# S32R372 register map
Vendor: Freescale Semiconductor, Inc.; Series: Qorivva; File version: 1.6
Registers are 32-bit, read-write, reset 0x0 unless marked. A register's access mark holds for its fields unless they carry their own. Offsets are from the block's base; [hi:lo] are bit positions; {n}, {i} and the like mark numbered series; 'fields as' and 'values as' point back to an identical list.

## SIUL2
Base 0xFFFC0000; register names take the prefix SIUL2_
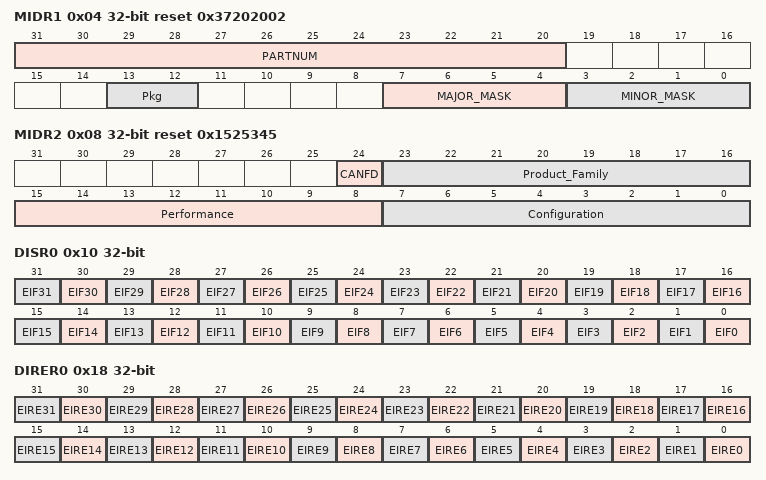
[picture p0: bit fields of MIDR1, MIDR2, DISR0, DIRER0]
0x04 MIDR1 ro reset 0x37202002 — SIUL2 MCU ID Register #1
  [31:20] PARTNUM — MCU Part Number
  [13:12] Pkg — Package details
    1=141MAPBGA Packeage; 2=257MAPBGA Package
  [7:4] MAJOR_MASK — Major Mask Revision
  [3:0] MINOR_MASK — Minor Mask Revision
0x08 MIDR2 ro reset 0x1525345 — SIUL2 MCU ID Register #2
  [24] CANFD
    0=CANFD is not supported; 1=CANFD is supported
  [23:16] Product_Family — Product Family Number
  [15:8] Performance — Performance of device, see
  [7:0] Configuration — Configuration of device, see
0x10 DISR0 — SIUL2 DMA/Interrupt Status Flag Register0
  [n] EIF{n} (n=4..31) — External Interrupt Status Flag x
    0=No interrupt event has occurred on the pad; 1=An interrupt event as defined by SIUL2_IREER[x] and SIUL2_IFEER[x] has occurred
  [n] EIF{n} (n=0..3) — External Interrupt Status Flag x
    0=No interrupt or DMA event has occurred on the pad; 1=An interrupt or DMA event as defined by SIUL2_IREER[x] and SIUL2_IFEER[x] has occurred
0x18 DIRER0 — SIUL2 DMA/Interrupt Request Enable Register0
  [n] EIRE{n} (n=4..31) — External Interrupt or DMA Request Enable x
    0=Interrupt or DMA requests from the corresponding EIF[x] bit are disabled; 1=Set EIF[x] bit causes an interrupt request
  [n] EIRE{n} (n=0..3) — External Interrupt or DMA Request Enable x
    0=Interrupt or DMA requests from the corresponding EIF[x] bit are disabled; 1=Set EIF[x] bit causes either a DMA or an interrupt request depending on DIRSR register
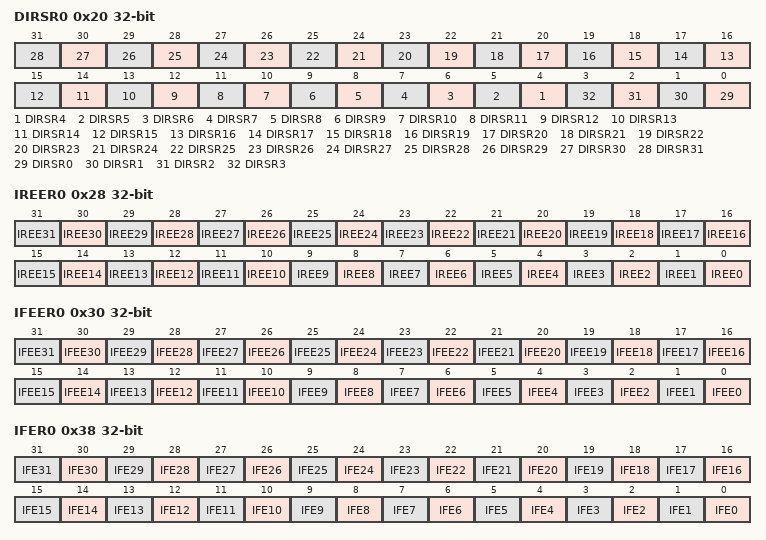
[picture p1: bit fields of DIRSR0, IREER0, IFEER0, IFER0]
0x20 DIRSR0 — SIUL2 DMA/Interrupt Request Select Register0
  [n] DIRSR{n} (n=4..31) — DMA/Interrupt Request Select Register-Selects between DMA request or external interrupt request when an edge-triggered event occurs on the corresponding pin
    0=Interrupt request is selected
  [n] DIRSR{n} (n=0..3) — DMA/Interrupt Request Select Register-Selects between DMA request or external interrupt request when an edge-triggered event occurs on the corresponding pin
    0=Interrupt request is selected; 1=DMA request is selected
0x28 IREER0 — SIUL2 Interrupt Rising-Edge Event Enable Register 0
  [all] fields
    0=Rising-edge event is disabled; 1=Rising-edge event is enabled
  [n] IREE{n} (n=0..31) — Enable rising-edge events to cause the EIF[x] bit to be set.
0x30 IFEER0 — SIUL2 Interrupt Falling-Edge Event Enable Register 0
  [all] fields
    0=Falling-edge event is disabled; 1=Falling-edge event is enabled
  [n] IFEE{n} (n=0..31) — Enable falling-edge events to cause the EIF[x] bit to be set.
0x38 IFER0 — SIUL2 Interrupt Filter Enable Register 0
  [all] fields
    0=Filter is disabled; 1=Filter is enabled
  [n] IFE{n} (n=0..31) — Enable digital glitch filter on the interrupt pad input.
{0x40+4i} IFMCR{i} (i=0..31) — SIUL2 Interrupt Filter Maximum Counter Register
  [3:0] MAXCNT — Maximum Interrupt Filter Counter setting
0xC0 IFCPR — SIUL2 Interrupt Filter Clock Prescaler Register
  [3:0] IFCP — Interrupt Filter Clock Prescaler setting
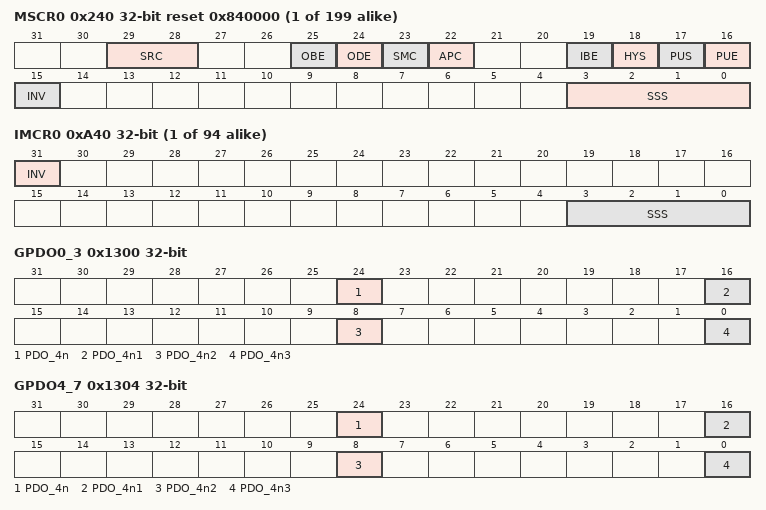
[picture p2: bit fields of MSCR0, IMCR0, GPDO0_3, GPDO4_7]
{0x240+4i} MSCR{i} (i=0..198) reset 0x840000 — SIUL2 Multiplexed Signal Configuration Register
  [29:28] SRC — Slew Rate Control
    0=Half drive strength with slew rate control; 1=Full drive strength with slew rate control; 2=Half drive strength without slew rate control; 3=Full drive strength without slew rate control
  [25] OBE — GPIO Output Buffer Enable
    0=Output driver disabled; 1=Output driver enabled
  [24] ODE — Open Drain EnableTo enable open drain both OBE and ODE bits need to be set.
    0=Open drain function disabled; 1=Open drain function enabled
  [23] SMC — Safe Mode Control
    0=Disable (the output buffer returns to its previous state when the chip leaves Safe mode); 1=Don't disable
  [22] APC — Analog Pad Control
    0=Disable (the switch is off); 1=Enable (another module can control the state of the switch)
  [19] IBE — Input Buffer Enable
    0=Disabled; 1=Enabled
  [18] HYS — Input Hysteresis
    0=Disabled; 1=Enabled
  [17] PUS — Pull Select
    0=Pulldown; 1=Pullup
  [16] PUE — Pull Enable
    0=Disabled; 1=Enabled
  [15] INV — Invert
    0=Don't invert; 1=Invert
  [3:0] SSS — Source Signal Select
{0xA40+4i} IMCR{i} (i=0..93) — SIUL2 Input Multiplexed Signal Configuration Register
  [31] INV — Invert
    0=Don't invert; 1=Invert
  [3:0] SSS — Source Signal Select
0x1300 GPDO0_3 — SIUL2 GPIO Pad Data Output Register
  [all] fields
    0=Logic low value is driven on the corresponding GPIO pad when the pad is configured as an output; 1=Logic high value is driven on the corresponding GPIO pad when the pad is configured as an output
  [24] PDO_4n — Pad Data Out
  [16] PDO_4n1 — Pad Data Out
  [8] PDO_4n2 — Pad Data Out
  [0] PDO_4n3 — Pad Data Out
0x1304 GPDO4_7 — SIUL2 GPIO Pad Data Output Register
  fields as GPDO0_3
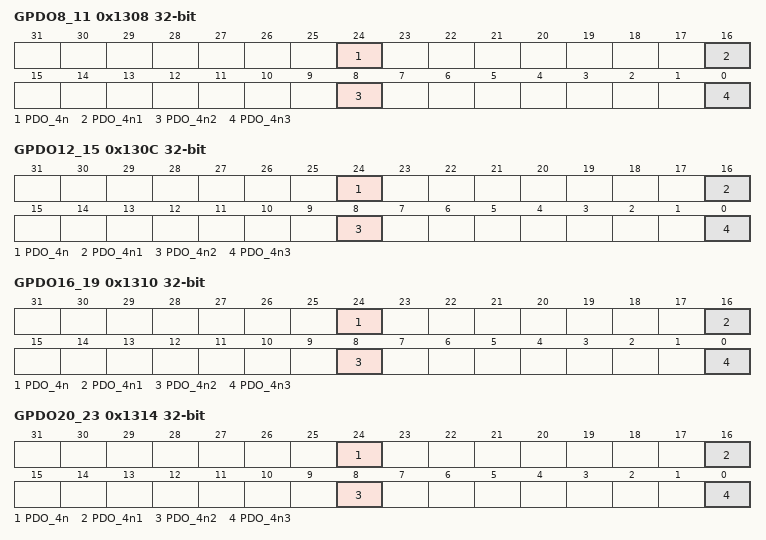
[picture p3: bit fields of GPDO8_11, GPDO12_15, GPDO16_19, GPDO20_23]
0x1308 GPDO8_11 — SIUL2 GPIO Pad Data Output Register
  fields as GPDO0_3
0x130C GPDO12_15 — SIUL2 GPIO Pad Data Output Register
  fields as GPDO0_3
0x1310 GPDO16_19 — SIUL2 GPIO Pad Data Output Register
  fields as GPDO0_3
0x1314 GPDO20_23 — SIUL2 GPIO Pad Data Output Register
  fields as GPDO0_3
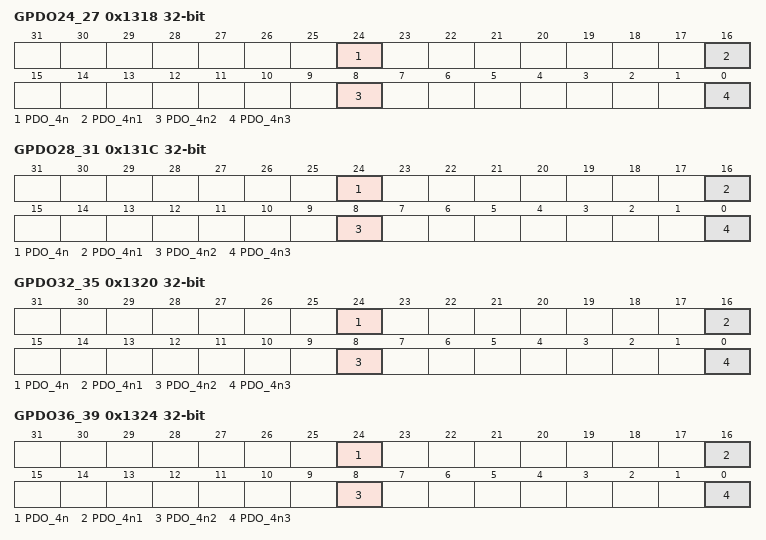
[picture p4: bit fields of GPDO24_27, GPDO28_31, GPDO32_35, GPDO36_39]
0x1318 GPDO24_27 — SIUL2 GPIO Pad Data Output Register
  fields as GPDO0_3
0x131C GPDO28_31 — SIUL2 GPIO Pad Data Output Register
  fields as GPDO0_3
0x1320 GPDO32_35 — SIUL2 GPIO Pad Data Output Register
  fields as GPDO0_3
0x1324 GPDO36_39 — SIUL2 GPIO Pad Data Output Register
  fields as GPDO0_3
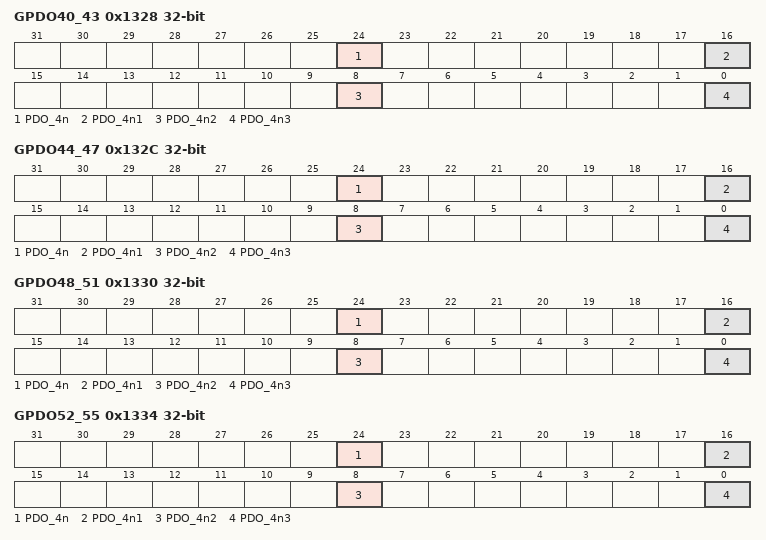
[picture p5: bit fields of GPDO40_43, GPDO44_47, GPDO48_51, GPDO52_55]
0x1328 GPDO40_43 — SIUL2 GPIO Pad Data Output Register
  fields as GPDO0_3
0x132C GPDO44_47 — SIUL2 GPIO Pad Data Output Register
  fields as GPDO0_3
0x1330 GPDO48_51 — SIUL2 GPIO Pad Data Output Register
  fields as GPDO0_3
0x1334 GPDO52_55 — SIUL2 GPIO Pad Data Output Register
  fields as GPDO0_3
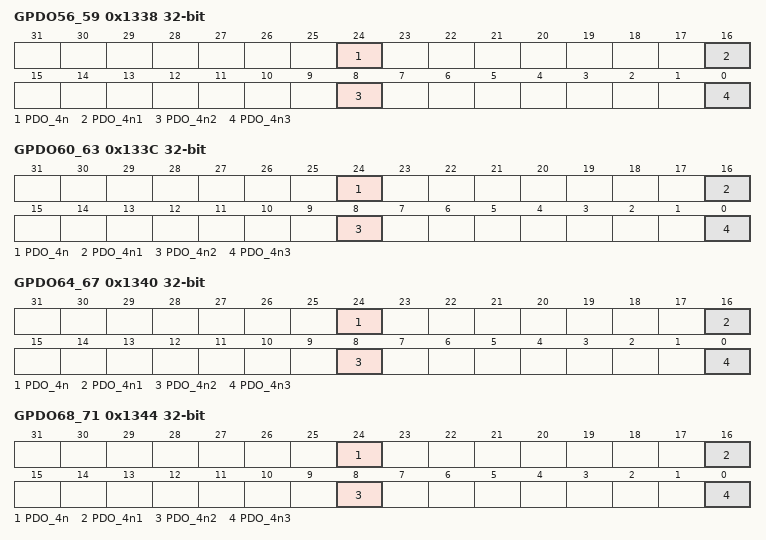
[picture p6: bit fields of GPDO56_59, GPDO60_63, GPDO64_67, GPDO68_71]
0x1338 GPDO56_59 — SIUL2 GPIO Pad Data Output Register
  fields as GPDO0_3
0x133C GPDO60_63 — SIUL2 GPIO Pad Data Output Register
  fields as GPDO0_3
0x1340 GPDO64_67 — SIUL2 GPIO Pad Data Output Register
  fields as GPDO0_3
0x1344 GPDO68_71 — SIUL2 GPIO Pad Data Output Register
  fields as GPDO0_3
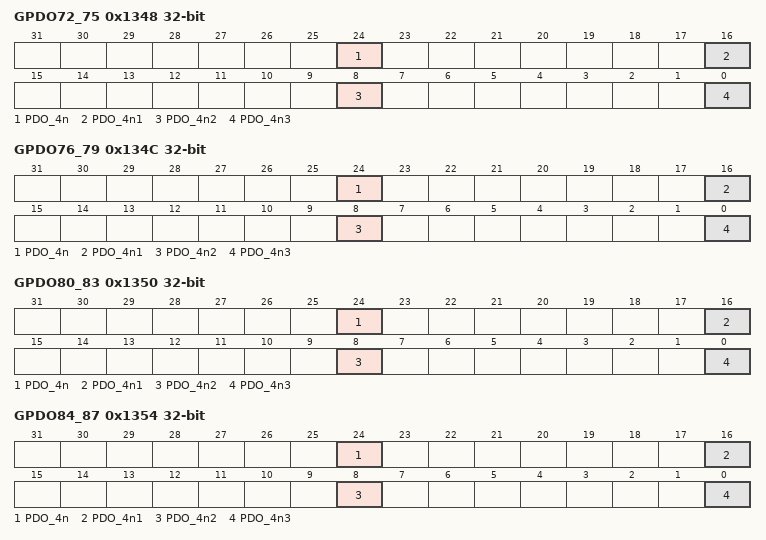
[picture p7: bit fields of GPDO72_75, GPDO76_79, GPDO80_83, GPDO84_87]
0x1348 GPDO72_75 — SIUL2 GPIO Pad Data Output Register
  fields as GPDO0_3
0x134C GPDO76_79 — SIUL2 GPIO Pad Data Output Register
  fields as GPDO0_3
0x1350 GPDO80_83 — SIUL2 GPIO Pad Data Output Register
  fields as GPDO0_3
0x1354 GPDO84_87 — SIUL2 GPIO Pad Data Output Register
  fields as GPDO0_3
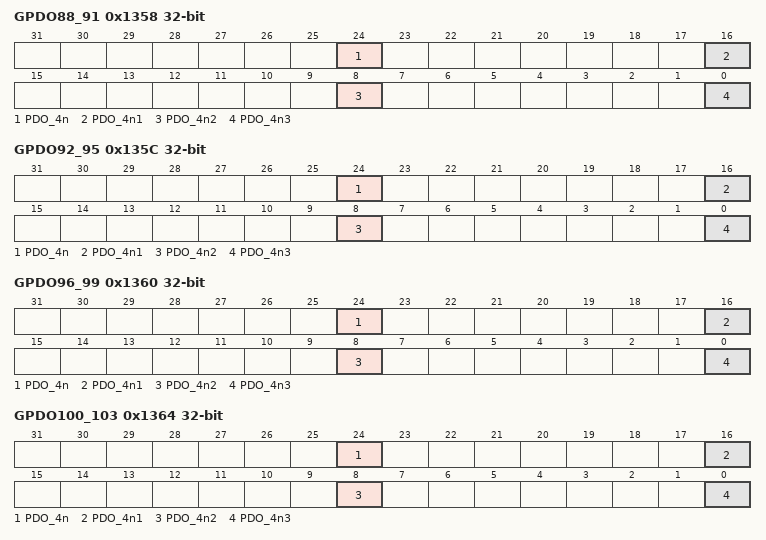
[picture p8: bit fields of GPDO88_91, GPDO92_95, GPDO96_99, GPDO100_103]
0x1358 GPDO88_91 — SIUL2 GPIO Pad Data Output Register
  fields as GPDO0_3
0x135C GPDO92_95 — SIUL2 GPIO Pad Data Output Register
  fields as GPDO0_3
0x1360 GPDO96_99 — SIUL2 GPIO Pad Data Output Register
  fields as GPDO0_3
0x1364 GPDO100_103 — SIUL2 GPIO Pad Data Output Register
  fields as GPDO0_3
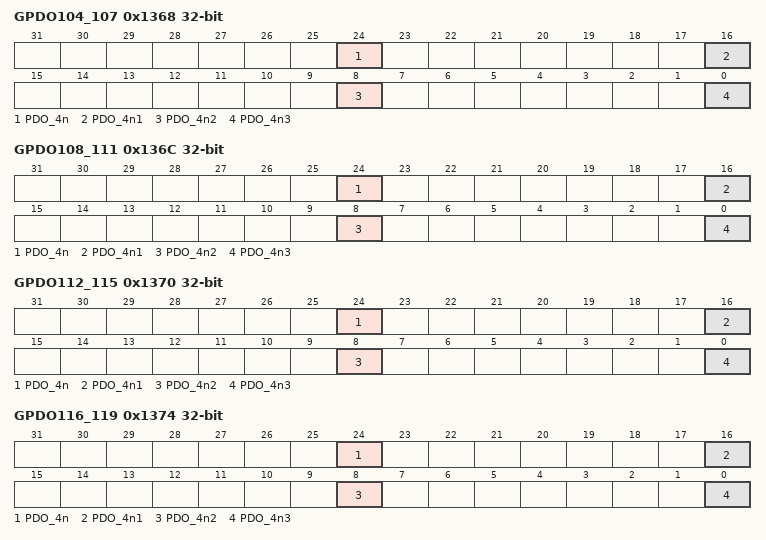
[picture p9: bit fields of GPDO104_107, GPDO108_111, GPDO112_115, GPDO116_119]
0x1368 GPDO104_107 — SIUL2 GPIO Pad Data Output Register
  fields as GPDO0_3
0x136C GPDO108_111 — SIUL2 GPIO Pad Data Output Register
  fields as GPDO0_3
0x1370 GPDO112_115 — SIUL2 GPIO Pad Data Output Register
  fields as GPDO0_3
0x1374 GPDO116_119 — SIUL2 GPIO Pad Data Output Register
  fields as GPDO0_3
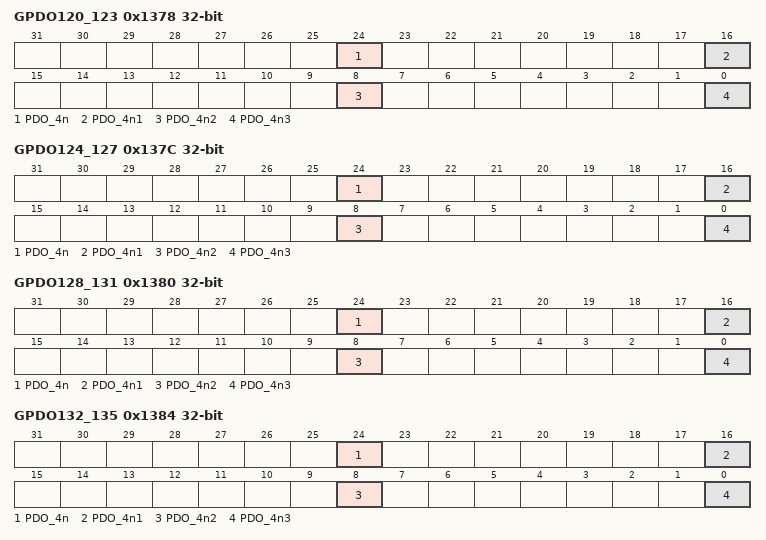
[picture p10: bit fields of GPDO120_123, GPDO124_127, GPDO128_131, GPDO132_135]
0x1378 GPDO120_123 — SIUL2 GPIO Pad Data Output Register
  fields as GPDO0_3
0x137C GPDO124_127 — SIUL2 GPIO Pad Data Output Register
  fields as GPDO0_3
0x1380 GPDO128_131 — SIUL2 GPIO Pad Data Output Register
  fields as GPDO0_3
0x1384 GPDO132_135 — SIUL2 GPIO Pad Data Output Register
  fields as GPDO0_3
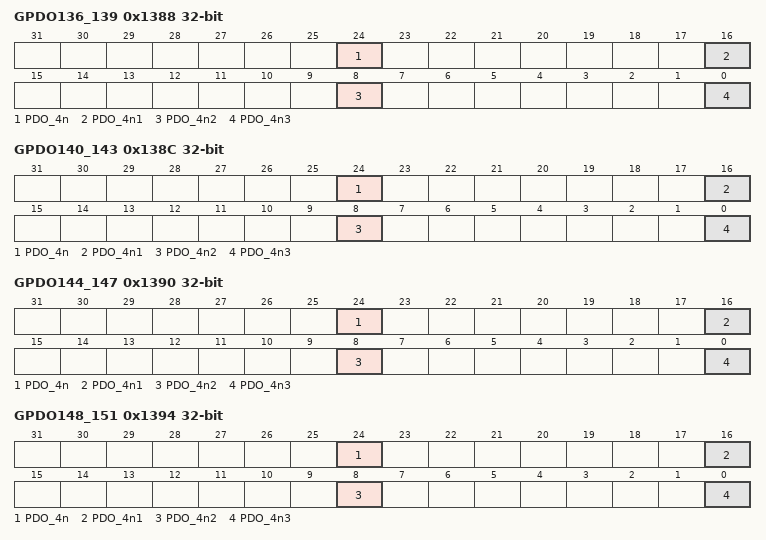
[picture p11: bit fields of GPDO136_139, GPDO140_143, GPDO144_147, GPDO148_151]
0x1388 GPDO136_139 — SIUL2 GPIO Pad Data Output Register
  fields as GPDO0_3
0x138C GPDO140_143 — SIUL2 GPIO Pad Data Output Register
  fields as GPDO0_3
0x1390 GPDO144_147 — SIUL2 GPIO Pad Data Output Register
  fields as GPDO0_3
0x1394 GPDO148_151 — SIUL2 GPIO Pad Data Output Register
  fields as GPDO0_3
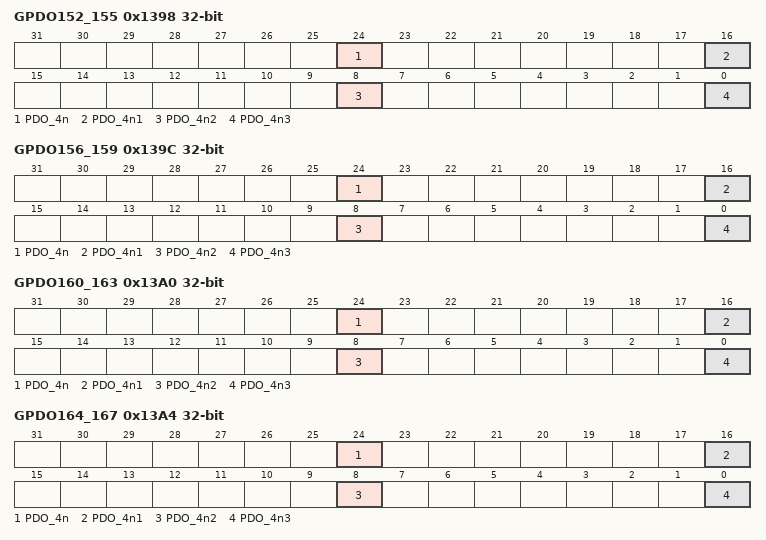
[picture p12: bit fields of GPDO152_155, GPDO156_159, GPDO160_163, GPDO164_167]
0x1398 GPDO152_155 — SIUL2 GPIO Pad Data Output Register
  fields as GPDO0_3
0x139C GPDO156_159 — SIUL2 GPIO Pad Data Output Register
  fields as GPDO0_3
0x13A0 GPDO160_163 — SIUL2 GPIO Pad Data Output Register
  fields as GPDO0_3
0x13A4 GPDO164_167 — SIUL2 GPIO Pad Data Output Register
  fields as GPDO0_3
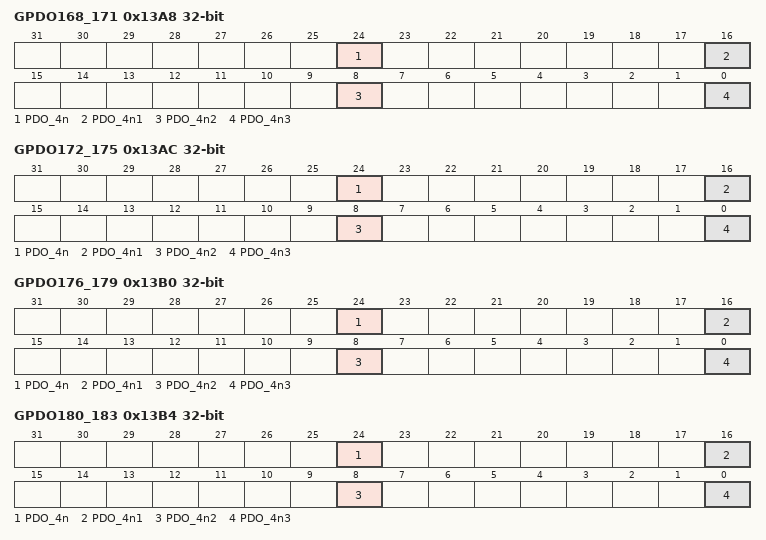
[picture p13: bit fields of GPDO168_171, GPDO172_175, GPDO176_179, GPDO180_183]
0x13A8 GPDO168_171 — SIUL2 GPIO Pad Data Output Register
  fields as GPDO0_3
0x13AC GPDO172_175 — SIUL2 GPIO Pad Data Output Register
  fields as GPDO0_3
0x13B0 GPDO176_179 — SIUL2 GPIO Pad Data Output Register
  fields as GPDO0_3
0x13B4 GPDO180_183 — SIUL2 GPIO Pad Data Output Register
  fields as GPDO0_3
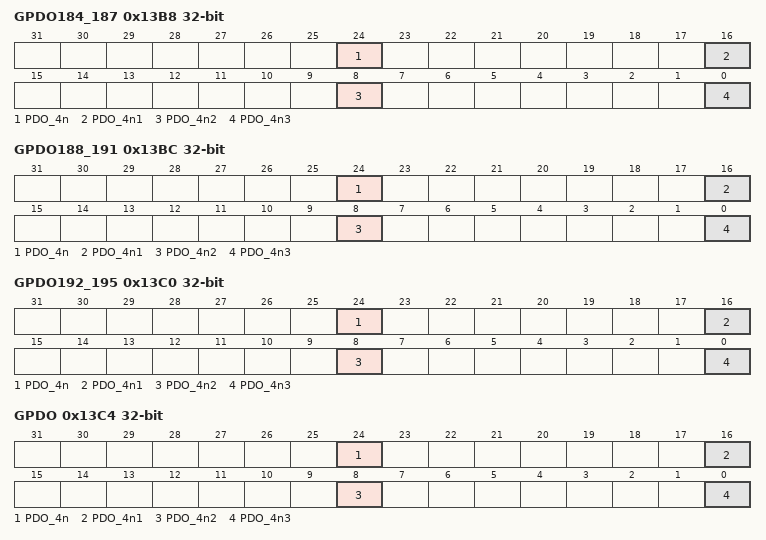
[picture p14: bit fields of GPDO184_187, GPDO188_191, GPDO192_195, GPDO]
0x13B8 GPDO184_187 — SIUL2 GPIO Pad Data Output Register
  fields as GPDO0_3
0x13BC GPDO188_191 — SIUL2 GPIO Pad Data Output Register
  fields as GPDO0_3
0x13C0 GPDO192_195 — SIUL2 GPIO Pad Data Output Register
  fields as GPDO0_3
0x13C4 GPDO — SIUL2 GPIO Pad Data Output Register
  fields as GPDO0_3
0x1500 GPDI0_3 ro — SIUL2 GPIO Pad Data Input Register
  [all] fields
    0=The value of the data in signal for the corresponding GPIO pad is logic low; 1=The value of the data in signal for the corresponding GPIO pad is logic high
  [24] PDI_4n — Pad Data In
  [16] PDI_4n1 — Pad Data In
  [8] PDI_4n2 — Pad Data In
  [0] PDI_4n3 — Pad Data In
0x1504 GPDI4_7 ro — SIUL2 GPIO Pad Data Input Register
  fields as GPDI0_3
0x1508 GPDI8_11 ro — SIUL2 GPIO Pad Data Input Register
  fields as GPDI0_3
0x150C GPDI12_15 ro — SIUL2 GPIO Pad Data Input Register
  fields as GPDI0_3
0x1510 GPDI16_19 ro — SIUL2 GPIO Pad Data Input Register
  fields as GPDI0_3
0x1514 GPDI20_23 ro — SIUL2 GPIO Pad Data Input Register
  fields as GPDI0_3
0x1518 GPDI24_27 ro — SIUL2 GPIO Pad Data Input Register
  fields as GPDI0_3
0x151C GPDI28_31 ro — SIUL2 GPIO Pad Data Input Register
  fields as GPDI0_3
0x1520 GPDI32_35 ro — SIUL2 GPIO Pad Data Input Register
  fields as GPDI0_3
0x1524 GPDI36_39 ro — SIUL2 GPIO Pad Data Input Register
  fields as GPDI0_3
0x1528 GPDI40_43 ro — SIUL2 GPIO Pad Data Input Register
  fields as GPDI0_3
0x152C GPDI44_47 ro — SIUL2 GPIO Pad Data Input Register
  fields as GPDI0_3
0x1530 GPDI48_51 ro — SIUL2 GPIO Pad Data Input Register
  fields as GPDI0_3
0x1534 GPDI52_55 ro — SIUL2 GPIO Pad Data Input Register
  fields as GPDI0_3
0x1538 GPDI56_59 ro — SIUL2 GPIO Pad Data Input Register
  fields as GPDI0_3
0x153C GPDI60_63 ro — SIUL2 GPIO Pad Data Input Register
  fields as GPDI0_3
0x1540 GPDI64_67 ro — SIUL2 GPIO Pad Data Input Register
  fields as GPDI0_3
0x1544 GPDI68_71 ro — SIUL2 GPIO Pad Data Input Register
  fields as GPDI0_3
0x1548 GPDI72_75 ro — SIUL2 GPIO Pad Data Input Register
  fields as GPDI0_3
0x154C GPDI76_79 ro — SIUL2 GPIO Pad Data Input Register
  fields as GPDI0_3
0x1550 GPDI80_83 ro — SIUL2 GPIO Pad Data Input Register
  fields as GPDI0_3
0x1554 GPDI84_87 ro — SIUL2 GPIO Pad Data Input Register
  fields as GPDI0_3
0x1558 GPDI88_91 ro — SIUL2 GPIO Pad Data Input Register
  fields as GPDI0_3
0x155C GPDI92_95 ro — SIUL2 GPIO Pad Data Input Register
  fields as GPDI0_3
0x1560 GPDI96_99 ro — SIUL2 GPIO Pad Data Input Register
  fields as GPDI0_3
0x1564 GPDI100_103 ro — SIUL2 GPIO Pad Data Input Register
  fields as GPDI0_3
0x1568 GPDI104_107 ro — SIUL2 GPIO Pad Data Input Register
  fields as GPDI0_3
0x156C GPDI108_111 ro — SIUL2 GPIO Pad Data Input Register
  fields as GPDI0_3
0x1570 GPDI112_115 ro — SIUL2 GPIO Pad Data Input Register
  fields as GPDI0_3
0x1574 GPDI116_119 ro — SIUL2 GPIO Pad Data Input Register
  fields as GPDI0_3
0x1578 GPDI120_123 ro — SIUL2 GPIO Pad Data Input Register
  fields as GPDI0_3
0x157C GPDI124_127 ro — SIUL2 GPIO Pad Data Input Register
  fields as GPDI0_3
0x1580 GPDI128_131 ro — SIUL2 GPIO Pad Data Input Register
  fields as GPDI0_3
0x1584 GPDI132_135 ro — SIUL2 GPIO Pad Data Input Register
  fields as GPDI0_3
0x1588 GPDI136_139 ro — SIUL2 GPIO Pad Data Input Register
  fields as GPDI0_3
0x158C GPDI140_143 ro — SIUL2 GPIO Pad Data Input Register
  fields as GPDI0_3
0x1590 GPDI144_147 ro — SIUL2 GPIO Pad Data Input Register
  fields as GPDI0_3
0x1594 GPDI148_151 ro — SIUL2 GPIO Pad Data Input Register
  fields as GPDI0_3
0x1598 GPDI152_155 ro — SIUL2 GPIO Pad Data Input Register
  fields as GPDI0_3
0x159C GPDI156_159 ro — SIUL2 GPIO Pad Data Input Register
  fields as GPDI0_3
0x15A0 GPDI160_163 ro — SIUL2 GPIO Pad Data Input Register
  fields as GPDI0_3
0x15A4 GPDI164_167 ro — SIUL2 GPIO Pad Data Input Register
  fields as GPDI0_3
0x15A8 GPDI168_171 ro — SIUL2 GPIO Pad Data Input Register
  fields as GPDI0_3
0x15AC GPDI172_175 ro — SIUL2 GPIO Pad Data Input Register
  fields as GPDI0_3
0x15B0 GPDI176_179 ro — SIUL2 GPIO Pad Data Input Register
  fields as GPDI0_3
0x15B4 GPDI180_183 ro — SIUL2 GPIO Pad Data Input Register
  fields as GPDI0_3
0x15B8 GPDI184_187 ro — SIUL2 GPIO Pad Data Input Register
  fields as GPDI0_3
0x15BC GPDI188_191 ro — SIUL2 GPIO Pad Data Input Register
  fields as GPDI0_3
0x15C0 GPDI192_195 ro — SIUL2 GPIO Pad Data Input Register
  fields as GPDI0_3
0x15C4 GPDI ro — SIUL2 GPIO Pad Data Input Register
  fields as GPDI0_3
{0x1700+2i} PGPDO{i} (i=0..12) 16-bit — SIUL2 Parallel GPIO Pad Data Out Register
  [15:0] PPDO — Parallel Pad Data Out
{0x1740+2i} PGPDI{i} (i=0..12) 16-bit ro — SIUL2 Parallel GPIO Pad Data In Register
  [15:0] PPDI — Parallel Pad Data In
{0x1780+4i} MPGPDO{i} (i=0..12) wo — SIUL2 Masked Parallel GPIO Pad Data Out Register
  [31:16] MASK
    0=The associated bit value in the MPPDO[x] field is ignored; 1=The associated bit value in the MPPDO[x] field is written
  [15:0] MPPDO — Masked Parallel Pad Data Out
